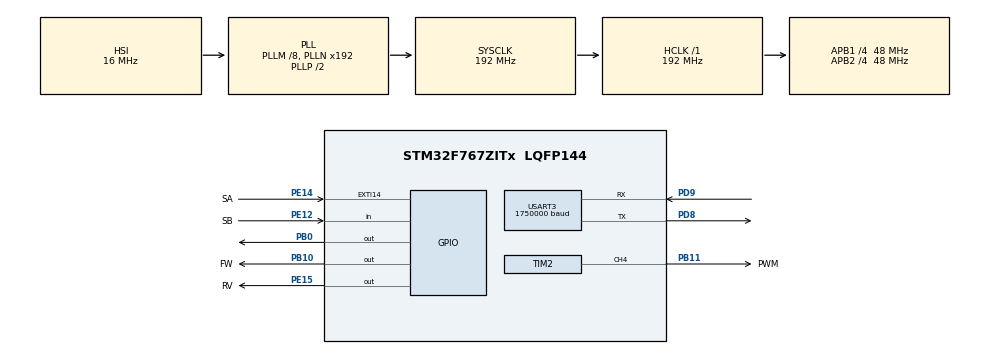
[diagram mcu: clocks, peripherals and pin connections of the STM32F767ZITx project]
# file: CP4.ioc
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Mcu.Family=STM32F7
Mcu.Name=STM32F767ZITx
Mcu.Package=LQFP144
NVIC.EXTI15_10_IRQn=true\:0\:0\:false\:false\:true\:true\:true
NVIC.PriorityGroup=NVIC_PRIORITYGROUP_4
NVIC.TIM3_IRQn=true\:0\:0\:false\:false\:true\:true\:true
NVIC.USART3_IRQn=true\:0\:0\:false\:false\:true\:true\:true
PB0.Signal=GPIO_Output
PB10.GPIO_Label=FW
PB10.Signal=GPIO_Output
PB11.GPIO_Label=PWM
PB11.Signal=S_TIM2_CH4
PD8.Mode=Asynchronous
PD8.Signal=USART3_TX
PD9.Mode=Asynchronous
PD9.Signal=USART3_RX
PE12.GPIO_Label=SB
PE12.Signal=GPIO_Input
PE14.GPIO_Label=SA
PE14.GPIO_ModeDefaultEXTI=GPIO_MODE_IT_RISING
PE14.Signal=GPXTI14
PE15.GPIO_Label=RV
PE15.Signal=GPIO_Output
ProjectManager.HeapSize=0x200
ProjectManager.StackSize=0x400
ProjectManager.TargetToolchain=STM32CubeIDE
RCC.AHBFreq_Value=192000000
RCC.APB1CLKDivider=RCC_HCLK_DIV4
RCC.APB1Freq_Value=48000000
RCC.APB1TimFreq_Value=96000000
RCC.APB2CLKDivider=RCC_HCLK_DIV4
RCC.APB2Freq_Value=48000000
RCC.APB2TimFreq_Value=96000000
RCC.CortexFreq_Value=192000000
RCC.HCLKFreq_Value=192000000
RCC.HSE_VALUE=25000000
RCC.HSI_VALUE=16000000
RCC.LSE_VALUE=32768
RCC.PLLM=8
RCC.SYSCLKFreq_VALUE=192000000
RCC.SYSCLKSource=RCC_SYSCLKSOURCE_PLLCLK
RCC.USBFreq_Value=192000000
RCC.VCOOutputFreq_Value=384000000
SH.S_TIM2_CH4.0=TIM2_CH4,PWM Generation4 CH4
TIM2.Channel-PWM\ Generation4\ CH4=TIM_CHANNEL_4
TIM2.Period=100-1
TIM2.Prescaler=4800-1
TIM3.AutoReloadPreload=TIM_AUTORELOAD_PRELOAD_DISABLE
TIM3.Period=1000-1
TIM3.Prescaler=96-1
USART3.BaudRate=1750000
USART3.VirtualMode-Asynchronous=VM_ASYNC
VP_TIM2_VS_ClockSourceINT.Mode=Internal
VP_TIM3_VS_ClockSourceINT.Mode=Internal
board=custom

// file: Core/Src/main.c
/* USER CODE BEGIN Header */
/**
  ******************************************************************************
  * @file           : main.c
  * @brief          : Main program body
  ******************************************************************************
  * @attention
  *
  * Copyright (c) 2022 STMicroelectronics.
  * All rights reserved.
  *
  * This software is licensed under terms that can be found in the LICENSE file
  * in the root directory of this software component.
  * If no LICENSE file comes with this software, it is provided AS-IS.
  *
  ******************************************************************************
  */

/* USER CODE END Header */
#include "main.h"
#include "tim.h"
#include "usart.h"
#include "gpio.h"

/* USER CODE BEGIN Includes */
#include "commands.h"
/* USER CODE END Includes */

void SystemClock_Config(void);

int main(void)
{

  /* MCU Configuration--------------------------------------------------------*/

  /* Reset of all peripherals, Initializes the Flash interface and the Systick. */
  HAL_Init();

  /* Configure the system clock */
  SystemClock_Config();

  /* Initialize all configured peripherals */
  MX_TIM3_Init();
  MX_GPIO_Init();
  MX_USART3_UART_Init();
  MX_TIM2_Init();
  /* USER CODE BEGIN 2 */

  HAL_UART_Receive_IT(&huart3, UART_RX_buffer, 1);
  send_UART(PROMPT);

  /* USER CODE END 2 */

  /* Infinite loop */
  /* USER CODE BEGIN WHILE */

  while (1)
  {
	  if(has_message_from_UART())
	  {
		  uint8_t message[BUFFER_SIZE];

		  read_UART((char*) message);

		  unsigned char cmd = check_command((char*) message);
		  exec_command[cmd]((char*) message);

		  while(is_transmitting_to_UART());

		  reset_UART();
		  send_UART(PROMPT);
	  }

    /* USER CODE END WHILE */

  }
}

void SystemClock_Config(void)
{
  RCC_OscInitTypeDef RCC_OscInitStruct = {0};
  RCC_ClkInitTypeDef RCC_ClkInitStruct = {0};

  /** Configure the main internal regulator output voltage
  */
  __HAL_RCC_PWR_CLK_ENABLE();
  __HAL_PWR_VOLTAGESCALING_CONFIG(PWR_REGULATOR_VOLTAGE_SCALE1);
  /** Initializes the RCC Oscillators according to the specified parameters
  * in the RCC_OscInitTypeDef structure.
  */
  RCC_OscInitStruct.OscillatorType = RCC_OSCILLATORTYPE_HSI;
  RCC_OscInitStruct.HSIState = RCC_HSI_ON;
  RCC_OscInitStruct.HSICalibrationValue = RCC_HSICALIBRATION_DEFAULT;
  RCC_OscInitStruct.PLL.PLLState = RCC_PLL_ON;
  RCC_OscInitStruct.PLL.PLLSource = RCC_PLLSOURCE_HSI;
  RCC_OscInitStruct.PLL.PLLM = 8;
  RCC_OscInitStruct.PLL.PLLN = 192;
  RCC_OscInitStruct.PLL.PLLP = RCC_PLLP_DIV2;
  RCC_OscInitStruct.PLL.PLLQ = 2;
  RCC_OscInitStruct.PLL.PLLR = 2;
  if (HAL_RCC_OscConfig(&RCC_OscInitStruct) != HAL_OK)
  {
    Error_Handler();
  }
  /** Activate the Over-Drive mode
  */
  if (HAL_PWREx_EnableOverDrive() != HAL_OK)
  {
    Error_Handler();
  }
  /** Initializes the CPU, AHB and APB buses clocks
  */
  RCC_ClkInitStruct.ClockType = RCC_CLOCKTYPE_HCLK|RCC_CLOCKTYPE_SYSCLK
                              |RCC_CLOCKTYPE_PCLK1|RCC_CLOCKTYPE_PCLK2;
  RCC_ClkInitStruct.SYSCLKSource = RCC_SYSCLKSOURCE_PLLCLK;
  RCC_ClkInitStruct.AHBCLKDivider = RCC_SYSCLK_DIV1;
  RCC_ClkInitStruct.APB1CLKDivider = RCC_HCLK_DIV4;
  RCC_ClkInitStruct.APB2CLKDivider = RCC_HCLK_DIV4;

  if (HAL_RCC_ClockConfig(&RCC_ClkInitStruct, FLASH_LATENCY_6) != HAL_OK)
  {
    Error_Handler();
  }
}

void Error_Handler(void)
{
  __disable_irq();
  while (1)
  {
  }
}
